AUTOSAR XML (schema 00045)
package /Cdm
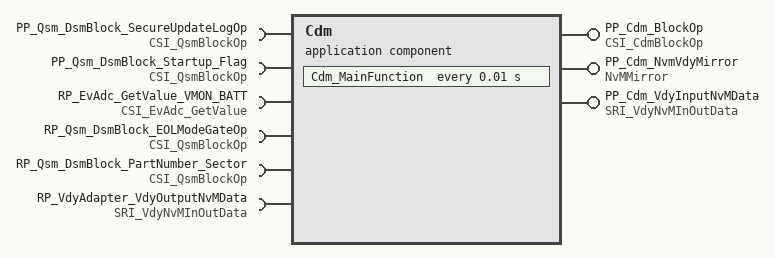
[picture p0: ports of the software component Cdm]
  application sw component type Cdm  # Configuration Data Management
    provide port PP_Cdm_BlockOp: provided-interface=CSI_CdmBlockOp
    provide port PP_Cdm_NvmVdyMirror: provided-interface=NvMMirror
    provide port PP_Cdm_VdyInputNvMData: provided-interface=SRI_VdyNvMInOutData
    6 x require port:
      PP_Qsm_DsmBlock_SecureUpdateLogOp: required-interface=CSI_QsmBlockOp
      PP_Qsm_DsmBlock_Startup_Flag: required-interface=CSI_QsmBlockOp
      RP_EvAdc_GetValue_VMON_BATT: required-interface=CSI_EvAdc_GetValue
      RP_Qsm_DsmBlock_EOLModeGateOp: required-interface=CSI_QsmBlockOp
      RP_Qsm_DsmBlock_PartNumber_Sector: required-interface=CSI_QsmBlockOp
      RP_VdyAdapter_VdyOutputNvMData: required-interface=SRI_VdyNvMInOutData
    behavior Cdm_IB: handle-termination-and-restart=NO-SUPPORT
      init event InitEvent_Cdm_InitFunction: start-on-event=Cdm_InitFunction
      timing event TimingEvent_Cdm_MainFunction: start-on-event=Cdm_MainFunction, period=0.01
      5 x operation invoked event:
        oie_PP_Cdm_BlockOp_Cdm_GetErrorStatus: start-on-event=Cdm_GetErrorStatus, operation=PP_Cdm_BlockOp.Cdm_GetErrorStatus
        oie_PP_Cdm_BlockOp_Cdm_ReadBlock: start-on-event=Cdm_ReadBlock, operation=PP_Cdm_BlockOp.Cdm_ReadBlock
        oie_PP_Cdm_BlockOp_Cdm_WriteBlock: start-on-event=Cdm_WriteBlock, operation=PP_Cdm_BlockOp.Cdm_WriteBlock
        oie_PP_Cdm_NvmVdyMirror_ReadRamBlockFromNvm: start-on-event=Cdm_VdyReadRamBlockMirror, operation=PP_Cdm_NvmVdyMirror.ReadRamBlockFromNvm
        oie_PP_Cdm_NvmVdyMirror_WriteRamBlockToNvm: start-on-event=Cdm_VdyWriteBlockMirror, operation=PP_Cdm_NvmVdyMirror.WriteRamBlockToNvm
      7 x runnable:
        Cdm_GetErrorStatus
        Cdm_InitFunction
          data-send-points:
            access dsp_VdyNvMInOutData: accessed-variable=PP_Cdm_VdyInputNvMData.VdyNvMInOutData
        Cdm_MainFunction
          13 x sync call, all with timeout=0.0:
            scp_GetPhyValue: operation=RP_EvAdc_GetValue_VMON_BATT.GetPhyValue
            scp_Qsm_GetErrorStatues: operation=PP_Qsm_DsmBlock_SecureUpdateLogOp.Qsm_GetErrorStatues
            scp_Qsm_GetErrorStatues0: operation=PP_Qsm_DsmBlock_Startup_Flag.Qsm_GetErrorStatues
            scp_Qsm_GetErrorStatues1: operation=RP_Qsm_DsmBlock_EOLModeGateOp.Qsm_GetErrorStatues
            scp_Qsm_GetErrorStatues2: operation=RP_Qsm_DsmBlock_PartNumber_Sector.Qsm_GetErrorStatues
            scp_Qsm_ReadBlock: operation=PP_Qsm_DsmBlock_SecureUpdateLogOp.Qsm_ReadBlock
            scp_Qsm_ReadBlock0: operation=PP_Qsm_DsmBlock_Startup_Flag.Qsm_ReadBlock
            scp_Qsm_ReadBlock1: operation=RP_Qsm_DsmBlock_EOLModeGateOp.Qsm_ReadBlock
            scp_Qsm_ReadBlock2: operation=RP_Qsm_DsmBlock_PartNumber_Sector.Qsm_ReadBlock
            scp_Qsm_WriteBlock: operation=PP_Qsm_DsmBlock_SecureUpdateLogOp.Qsm_WriteBlock
            scp_Qsm_WriteBlock0: operation=PP_Qsm_DsmBlock_Startup_Flag.Qsm_WriteBlock
            scp_Qsm_WriteBlock1: operation=RP_Qsm_DsmBlock_EOLModeGateOp.Qsm_WriteBlock
            scp_Qsm_WriteBlock2: operation=RP_Qsm_DsmBlock_PartNumber_Sector.Qsm_WriteBlock
        Cdm_ReadBlock
        Cdm_VdyReadRamBlockMirror
        Cdm_VdyWriteBlockMirror
          data-receive-point-by-arguments:
            access drparg_VdyNvMInOutData: accessed-variable=RP_VdyAdapter_VdyOutputNvMData.VdyNvMInOutData
        Cdm_WriteBlock
  swc implementation CdmImpl: programming-language=C, sw-version=0.0.1, vendor-id=0, behavior=Cdm_IB
    code-descriptors:
      code CodeGen: artifact-descriptors=[{short-label=SWSRC, category=SWSRC}, {short-label=SWHDR, category=SWHDR}]
    resource consumption Resource
      memory section CODE: sw-addrmethod=CODE
      memory section VAR_UNSPECIFIED: sw-addrmethod=VAR
